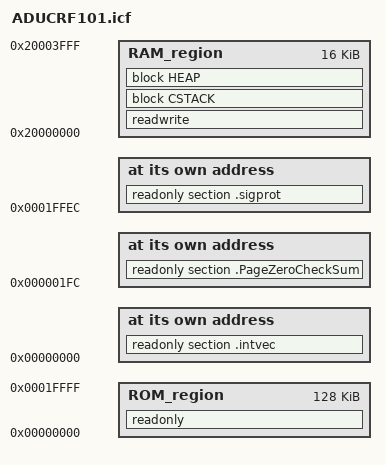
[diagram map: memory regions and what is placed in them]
/**
 * Copyright (c) 2014, Analog Devices, Inc.  All rights reserved.
 *
 * Redistribution and use in source and binary forms, with or without
 * modification, are permitted (subject to the limitations in the
 * disclaimer below) provided that the following conditions are met:
 *
 * - Redistributions of source code must retain the above copyright
 *   notice, this list of conditions and the following disclaimer.
 *
 * - Redistributions in binary form must reproduce the above copyright
 *   notice, this list of conditions and the following disclaimer in the
 *   documentation and/or other materials provided with the
 *   distribution.
 *
 * - Neither the name of Analog Devices, Inc. nor the names of its
 *   contributors may be used to endorse or promote products derived
 *   from this software without specific prior written permission.
 *
 * NO EXPRESS OR IMPLIED LICENSES TO ANY PARTY'S PATENT RIGHTS ARE
 * GRANTED BY THIS LICENSE.  THIS SOFTWARE IS PROVIDED BY THE COPYRIGHT
 * HOLDERS AND CONTRIBUTORS "AS IS" AND ANY EXPRESS OR IMPLIED
 * WARRANTIES, INCLUDING, BUT NOT LIMITED TO, THE IMPLIED WARRANTIES OF
 * MERCHANTABILITY AND FITNESS FOR A PARTICULAR PURPOSE ARE
 * DISCLAIMED. IN NO EVENT SHALL THE COPYRIGHT OWNER OR CONTRIBUTORS BE
 * LIABLE FOR ANY DIRECT, INDIRECT, INCIDENTAL, SPECIAL, EXEMPLARY, OR
 * CONSEQUENTIAL DAMAGES (INCLUDING, BUT NOT LIMITED TO, PROCUREMENT OF
 * SUBSTITUTE GOODS OR SERVICES; LOSS OF USE, DATA, OR PROFITS; OR
 * BUSINESS INTERRUPTION) HOWEVER CAUSED AND ON ANY THEORY OF LIABILITY,
 * WHETHER IN CONTRACT, STRICT LIABILITY, OR TORT (INCLUDING NEGLIGENCE
 * OR OTHERWISE) ARISING IN ANY WAY OUT OF THE USE OF THIS SOFTWARE, EVEN
 * IF ADVISED OF THE POSSIBILITY OF SUCH DAMAGE.
 */
/*###ICF### Section handled by ICF editor, don't touch! ****/
/*-Editor annotation file-*/
/* IcfEditorFile="$TOOLKIT_DIR$\config\ide\IcfEditor\cortex_v1_0.xml" */
/*-Specials-*/
define symbol __ICFEDIT_intvec_start__ = 0x00000000;
/*-Memory Regions-*/
define symbol __ICFEDIT_region_ROM_start__ = 0x00000000;
define symbol __ICFEDIT_region_ROM_end__   = 0x0001FFFF;
define symbol __ICFEDIT_region_RAM_start__ = 0x20000000;
define symbol __ICFEDIT_region_RAM_end__   = 0x20003FFF;
/*-Sizes-*/
define symbol __ICFEDIT_size_cstack__ = 0x400;
define symbol __ICFEDIT_size_heap__   = 0x200;
/**** End of ICF editor section. ###ICF###*/


define memory mem with size = 4G;
define region ROM_region   = mem:[from __ICFEDIT_region_ROM_start__   to __ICFEDIT_region_ROM_end__];
define region RAM_region   = mem:[from __ICFEDIT_region_RAM_start__   to __ICFEDIT_region_RAM_end__];

define block CSTACK    with alignment = 8, size = __ICFEDIT_size_cstack__   { };
define block HEAP      with alignment = 8, size = __ICFEDIT_size_heap__     { };

initialize by copy { readwrite };
do not initialize  { section .noinit };
do not initialize  { section .mainstackarea };

place at address mem:__ICFEDIT_intvec_start__ { readonly section .intvec };
place at address mem:0x1FC                    { readonly section .PageZeroCheckSum };
place at address mem:0x1FFEC                  { readonly section .sigprot };

place in ROM_region   { readonly };
place in RAM_region   { readwrite,
                        block CSTACK, block HEAP };
